# PIC18LF1220 register map
Vendor: Microchip
Architecture 18xxxx. Special function registers and configuration words.
Registers are 8-bit, read-write, no defined reset value unless marked. A register's access mark holds for its fields unless they carry their own. Addresses are absolute, and some are shared; only a register's first bit layout is shown; lines under a group give offsets from that group; [hi:lo] are bit positions; {n}, {i} and the like mark numbered series; 'fields as' and 'values as' point back to an identical list; <NAME> marks a mode.

## Further device data
pins=1: MCLR/VPP/RA5; 2: VSS; 3: AVSS; 4: RA2/AN2/VREF-; 5: RA3/AN3/VREF+; 6: RB0/AN4/INT0; 7: RB1/AN5/TX/CK/INT1; 8: RB4/AN6/RX/DT/KBI0; 9: RB5/PGM/KBI1; 10: RB6/PGC/T1OSO/T13CKI/P1C/KBI2; 11: RB7/PGD/T1OSI/P1D/KBI3; 12: AVDD; 13: AVDD; 14: VDD; 15: OSC2/CLKO/RA6; 16: OSC1/CLKI/RA7; 17: RB2/P1B/INT2; 18: RB3/CCP1/P1A; 19: RA0/AN0; 20: RA1/AN1/LVDIN; 21: RA4/T0CKI

## CONFIG — Configuration words, addresses in ProgramSpace
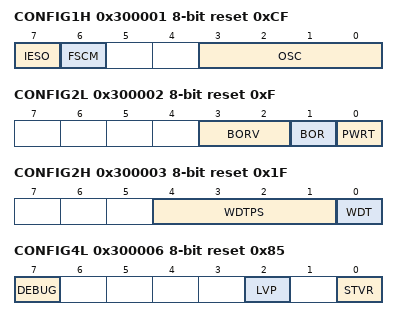
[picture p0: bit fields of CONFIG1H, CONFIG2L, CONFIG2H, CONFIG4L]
0x300001 CONFIG1H reset 0xCF
  [7] IESO — Internal External Switchover bit
    1=ON (Internal External Switchover mode enabled); 0=OFF (Internal External Switchover mode disabled)
  [6] FSCM — Fail-Safe Clock Monitor Enable bit
    1=ON (Fail-Safe Clock Monitor enabled); 0=OFF (Fail-Safe Clock Monitor disabled)
  [3:0] OSC — Oscillator Selection bits
    0b11xx=RC (External RC oscillator, CLKO function on RA6); 9=INTIO1 (Internal RC oscillator, CLKO function on RA6 and port function on RA7); 8=INTIO2 (Internal RC oscillator, port function on RA6 and port function on RA7); 7=RCIO (External RC oscillator, port function on RA6); 6=HSPLL (HS oscillator, PLL enabled (clock frequency = 4 x FOSC1)); 5=ECIO (EC oscillator, port function on RA6); 4=EC (EC oscillator, CLKO function on RA6); 2=HS (HS Oscillator); 1=XT (XT Oscillator); 0=LP (LP Oscillator)
0x300002 CONFIG2L reset 0xF
  [3:2] BORV — Brown-out Reset Voltage bits
    2=VBOR set to 2.7V; 1=VBOR set to 4.2V; 0=VBOR set to 4.5V
  [1] BOR — Brown-out Reset Enable bit
    1=ON (Brown-out Reset enabled); 0=OFF (Brown-out Reset disabled)
  [0] PWRT — Power-up Timer Enable bit
    1=OFF (PWRT disabled); 0=ON (PWRT enabled)
0x300003 CONFIG2H reset 0x1F
  [4:1] WDTPS — Watchdog Timer Postscale Select bits
    15=1:32768; 14=1:16384; 13=1:8192; 12=1:4096; 11=1:2048; 10=1:1024; 9=1:512; 8=1:256; 7=1:128; 6=1:64; 5=1:32; 4=1:16; 3=1:8; 2=1:4; 1=1:2; 0=1:1
  [0] WDT — Watchdog Timer Enable bit
    1=ON (WDT enabled); 0=OFF (WDT disabled (control is placed on the SWDTEN bit))
0x300005 CONFIG3H reset 0x80
  [7] MCLRE — MCLR Pin Enable bit
    1=ON (MCLR pin enabled, RA5 input pin disabled); 0=OFF (RA5 input pin enabled, MCLR disabled)
0x300006 CONFIG4L reset 0x85
  [7] DEBUG — Background Debugger Enable bit
    1=OFF (Background debugger disabled, RB6 and RB7 configured as general purpose I/O pins); 0=ON (Background debugger enabled, RB6 and RB7 are dedicated to In-Circuit Debug)
  [2] LVP — Low-Voltage ICSP Enable bit
    1=ON (Low-Voltage ICSP enabled); 0=OFF (Low-Voltage ICSP disabled)
  [0] STVR — Stack Full/Underflow Reset Enable bit
    1=ON (Stack full/underflow will cause Reset); 0=OFF (Stack full/underflow will not cause Reset)
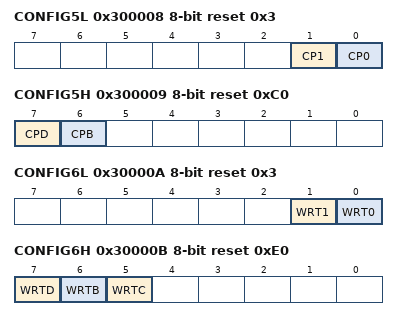
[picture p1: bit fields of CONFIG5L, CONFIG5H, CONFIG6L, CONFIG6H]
0x300008 CONFIG5L reset 0x3
  [1] CP1 — Code Protection bit
    1=OFF (Block 1 (000800-000FFFh) not code-protected); 0=ON (Block 1 (000800-000FFFh) code-protected)
  [0] CP0 — Code Protection bit
    1=OFF (Block 0 (00200-0007FFh) not code-protected); 0=ON (Block 0 (00200-0007FFh) code-protected)
0x300009 CONFIG5H reset 0xC0
  [7] CPD — Data EEPROM Code Protection bit
    1=OFF (Data EEPROM not code-protected); 0=ON (Data EEPROM code-protected)
  [6] CPB — Boot Block Code Protection bit
    1=OFF (Boot Block (000000-0001FFh) not code-protected); 0=ON (Boot Block (000000-0001FFh) code-protected)
0x30000A CONFIG6L reset 0x3
  [1] WRT1 — Write Protection bit
    1=OFF (Block 1 (000800-000FFFh) not write-protected); 0=ON (Block 1 (000800-000FFFh) write-protected)
  [0] WRT0 — Write Protection bit
    1=OFF (Block 0 (00200-0007FFh) not write-protected); 0=ON (Block 0 (00200-000F7Fh) write-protected)
0x30000B CONFIG6H reset 0xE0
  [7] WRTD — Data EEPROM Write Protection bit
    1=OFF (Data EEPROM not write-protected); 0=ON (Data EEPROM write-protected)
  [6] WRTB — Boot Block Write Protection bit
    1=OFF (Boot Block (000000-0001FFh) not write-protected); 0=ON (Boot Block (000000-0001FFh) write-protected)
  [5] WRTC — Configuration Register Write Protection bit
    1=OFF (Configuration registers (300000-3000FFh) not write-protected); 0=ON (Configuration registers (300000-3000FFh) write-protected)
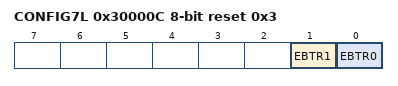
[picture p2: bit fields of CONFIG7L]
0x30000C CONFIG7L reset 0x3
  [1] EBTR1 — Table Read Protection bit
    1=OFF (Block 1 (000800-000FFFh) not protected from table reads executed in other blocks); 0=ON (Block 1 (000800-000FFFh) protected from table reads executed in other blocks)
  [0] EBTR0 — Table Read Protection bit
    1=OFF (Block 0 (00200-0007FFh) not protected from table reads executed in other blocks); 0=ON (Block 0 (00200-0007FFh) protected from table reads executed in other blocks)
0x30000D CONFIG7H reset 0x40
  [6] EBTRB — Boot Block Table Read Protection bit
    1=OFF (Boot Block (000000-0001FFh) not protected from table reads executed in other blocks); 0=ON (Boot Block (000000-0001FFh) protected from table reads executed in other blocks)
